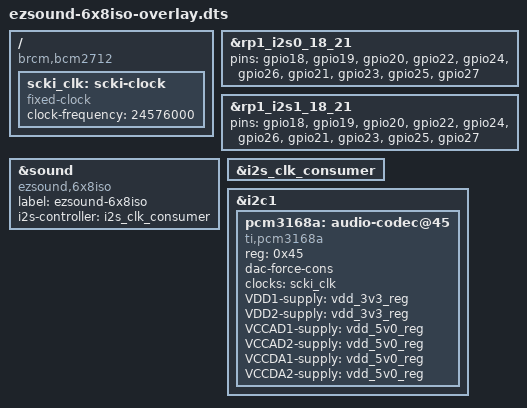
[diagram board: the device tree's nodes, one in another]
//Device tree overlay for ezsound 6x8iso card
/dts-v1/;
/plugin/;

/ {
    // Pi5 only
    compatible = "brcm,bcm2712";

    // Set GPIOs for the RP1 I2S blocks to use
    // (there is one each for clk producer/consumer modes)
    fragment@0 {
        target = <&rp1_i2s0_18_21>;
        __overlay__ {
            pins = "gpio18", "gpio19", "gpio20", "gpio22", "gpio24", "gpio26",
                   "gpio21", "gpio23", "gpio25", "gpio27";
        };
    };

    fragment@1 {
        target = <&rp1_i2s1_18_21>;
        __overlay__ {
            pins = "gpio18", "gpio19", "gpio20", "gpio22", "gpio24", "gpio26",
                   "gpio21", "gpio23", "gpio25", "gpio27";
        };
    };

    fragment@2 {
        target = <&sound>;
        __overlay__ {
	    compatible = "ezsound,6x8iso";
            label = "ezsound-6x8iso";
            i2s-controller = <&i2s_clk_consumer>;
            status = "okay";
        };
    };

    fragment@3 {
        target-path = "/";
        __overlay__ {
            scki_clk: scki-clock {
                #clock-cells = <0>;
                compatible = "fixed-clock";
                clock-frequency = <24576000>;
            };
        };
    };

    // Bring the I2S clock consumer block up
    fragment@4 {
        target = <&i2s_clk_consumer>;
        __overlay__ {
            #sound-dai-cells = <0>;
            status = "okay";
        };
    };

    fragment@5 {
        target = <&i2c1>;
        __overlay__ {
            #address-cells = <1>;
            #size-cells = <0>;

            pcm3168a: audio-codec@45 {
                #sound-dai-cells = <1>;
                compatible = "ti,pcm3168a";
                status = "okay";
                reg = <0x45>;
                dac-force-cons;
                clocks = <&scki_clk>;
                clock-names = "scki";
                VDD1-supply = <&vdd_3v3_reg>;
                VDD2-supply = <&vdd_3v3_reg>;
                VCCAD1-supply = <&vdd_5v0_reg>;
                VCCAD2-supply = <&vdd_5v0_reg>;
                VCCDA1-supply = <&vdd_5v0_reg>;
                VCCDA2-supply = <&vdd_5v0_reg>;
            };
        };
    };
};
